# STM32F205xx register map
File version: 1.0
Registers are 32-bit, read-write, reset 0x0 unless marked. A register's access mark holds for its fields unless they carry their own. Offsets are from the block's base; [hi:lo] are bit positions; {n}, {i} and the like mark numbered series; 'fields as' and 'values as' point back to an identical list.

## TIM2 — TIM
Base 0x40000000
Same registers: TIM5 0x40000C00
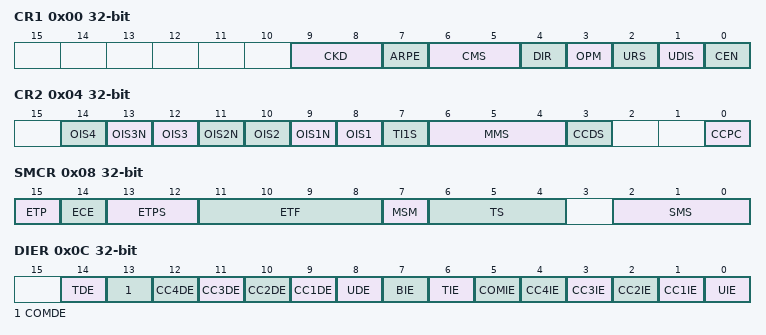
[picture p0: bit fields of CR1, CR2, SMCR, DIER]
0x00 CR1 — TIM control register 1
  [9:8] CKD — CKD[1:0] bits (clock division)
    0=DIV1 (tDTS=tCK_INT); 1=DIV2 (tDTS=2*tCK_INT); 2=DIV4 (tDTS=4*tCK_INT)
  [7] ARPE — Auto-reload preload enable
  [6:5] CMS — CMS[1:0] bits (Center-aligned mode selection)
  [4] DIR — Direction
    0=UP (Timer counter counts up); 1=DOWN (Timer counter counts down)
  [3] OPM — One pulse mode
    1=SINGLE (Counter stops counting at the next update event); 0=REPETITIVE (Counter is not stopped at update event)
  [2] URS — Update request source
    0=REGULAR (Counter overflow/underflow, Setting the UG bit or Update generation through the slave mode controller generates an update request); 1=COUNTER (Only counter overflow/underflow generates an update request)
  [1] UDIS — Update disable
  [0] CEN — Counter enable
0x04 CR2 — TIM control register 2
  [2n+6] OIS{n} (n=1..4) — Output Idle state {n} (OC{n} output)
  [13] OIS3N — Output Idle state 3 (OC3N output)
  [11] OIS2N — Output Idle state 2 (OC2N output)
  [9] OIS1N — Output Idle state 1 (OC1N output)
  [7] TI1S — TI1 Selection
  [6:4] MMS — MMS[2:0] bits (Master Mode Selection)
    0=RESET (UG bit from the TIMx_EGR register is used as trigger output); 1=ENABLE (Counter Enable signal (CNT_EN) is used as trigger output); 2=UPDATE (Update event is used as trigger output); 3=CC1IF (CC1 capture or a compare match is used as trigger output); {v}=OC{v-3}REF (OC{v-3}REF signal is used as trigger output) (v=4..7)
  [3] CCDS — Capture/Compare DMA Selection
    0=CC (CCx DMA request sent when CCx event occurs); 1=UPDATE (CCx DMA requests sent when update event occurs)
  [0] CCPC — Capture/Compare Preloaded Control
0x08 SMCR — TIM slave mode control register
  [15] ETP — External trigger polarity
  [14] ECE — External clock enable
  [13:12] ETPS — ETPS[1:0] bits (External trigger prescaler)
  [11:8] ETF — ETF[3:0] bits (External trigger filter)
  [7] MSM — Master/slave mode
  [6:4] TS — TS[2:0] bits (Trigger selection)
    {v}=ITR{v} (Internal Trigger {v} (ITR{v}) is used as trigger input) (v=0..3); 4=TI1F_ED (TI1 Edge Detector (TI1F_ED) is used as trigger input); 5=TI1FP1 (Filtered Timer Input 1 (TI1FP1) is used as trigger input); 6=TI2FP2 (Filtered Timer Input 2 (TI12P2) is used as trigger input); 7=ETRF (Filtered external Trigger (ETRF) is used as trigger input)
  [2:0] SMS — SMS[2:0] bits (Slave mode selection)
    1=X2_TI1 (Quadrature encoder mode 1, x2 mode - Counter counts up/down on TI1FP1 edge depending on TI2FP2 level); 2=X2_TI2 (Quadrature encoder mode 2, x2 mode - Counter counts up/down on TI2FP2 edge depending on TI1FP1 level); 3=X4_TI12 (Quadrature encoder mode 3, x4 mode - Counter counts up/down on both TI1FP1 and TI2FP2 edges depending on the level of the other input); 0=DISABLED (Slave mode disabled); 4=RESET (Reset Mode - Rising edge of the selected trigger input (TRGI) reinitializes the counter); 5=GATED (Gated Mode - The counter clock is enabled when the trigger input (TRGI) is high); 6=TRIGGER (Trigger Mode - The counter starts at a rising edge of the trigger TRGI)
0x0C DIER — TIM DMA/interrupt enable register
  [14] TDE — Trigger DMA request enable
  [13] COMDE — COM DMA request enable
  [n+8] CC{n}DE (n=1..4) — Capture/Compare {n} DMA request enable
  [8] UDE — Update DMA request enable
  [7] BIE — Break interrupt enable
  [6] TIE — Trigger interrupt enable
  [5] COMIE — COM interrupt enable
  [n] CC{n}IE (n=1..4) — Capture/Compare {n} interrupt enable
  [0] UIE — Update interrupt enable
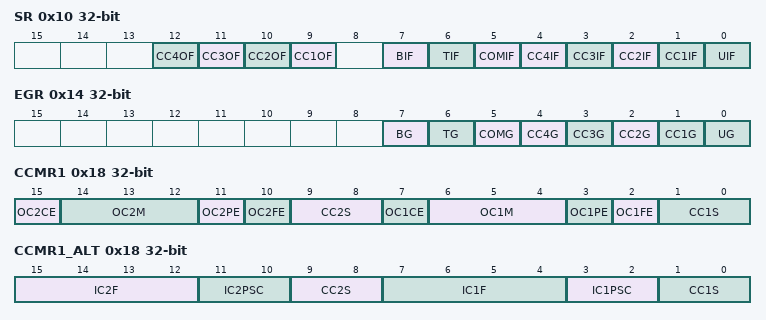
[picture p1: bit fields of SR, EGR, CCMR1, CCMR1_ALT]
0x10 SR — TIM status register
  [n+8] CC{n}OF (n=1..4) — Capture/Compare {n} Overcapture Flag
  [7] BIF — Break interrupt Flag
  [6] TIF — Trigger interrupt Flag
  [5] COMIF — COM interrupt Flag
  [n] CC{n}IF (n=1..4) — Capture/Compare {n} interrupt Flag
  [0] UIF — Update interrupt Flag
0x14 EGR — TIM event generation register
  [7] BG — Break Generation
  [6] TG — Trigger Generation
  [5] COMG — Capture/Compare Control Update Generation
  [n] CC{n}G (n=1..4) — Capture/Compare {n} Generation
  [0] UG — Update Generation
0x18 CCMR1 — TIM capture/compare mode register 1
  [15] OC2CE — Output Compare 2 Clear Enable
  [14:12] OC2M — OC2M[2:0] bits (Output Compare 2 Mode)
  [11] OC2PE — Output Compare 2 Preload enable
  [10] OC2FE — Output Compare 2 Fast enable
  [9:8] CC2S — CC2S[1:0] bits (Capture/Compare 2 Selection)
  [7] OC1CE — Output Compare 1Clear Enable
  [6:4] OC1M — OC1M[2:0] bits (Output Compare 1 Mode)
  [3] OC1PE — Output Compare 1 Preload enable
  [2] OC1FE — Output Compare 1 Fast enable
  [1:0] CC1S — CC1S[1:0] bits (Capture/Compare 1 Selection)
0x18 CCMR1_ALT (alternate view of CCMR1) — TIM capture/compare mode register 1
  [15:12] IC2F — IC2F[3:0] bits (Input Capture 2 Filter)
  [11:10] IC2PSC — IC2PSC[1:0] bits (Input Capture 2 Prescaler)
  [9:8] CC2S — CC2S[1:0] bits (Capture/Compare 2 Selection)
  [7:4] IC1F — IC1F[3:0] bits (Input Capture 1 Filter)
  [3:2] IC1PSC — IC1PSC[1:0] bits (Input Capture 1 Prescaler)
  [1:0] CC1S — CC1S[1:0] bits (Capture/Compare 1 Selection)
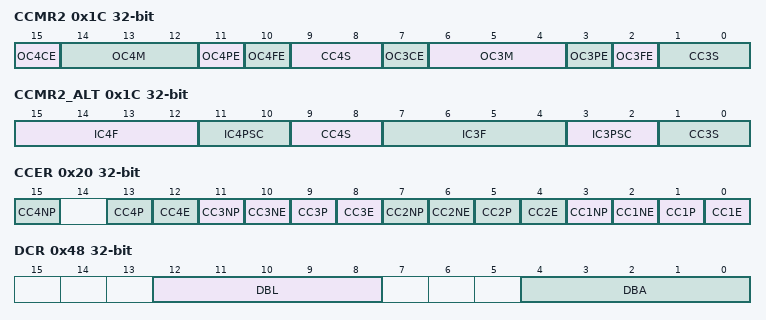
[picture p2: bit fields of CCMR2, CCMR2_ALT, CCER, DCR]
0x1C CCMR2 — TIM capture/compare mode register 2
  [15] OC4CE — Output Compare 4 Clear Enable
  [14:12] OC4M — OC4M[2:0] bits (Output Compare 4 Mode)
  [11] OC4PE — Output Compare 4 Preload enable
  [10] OC4FE — Output Compare 4 Fast enable
  [9:8] CC4S — CC4S[1:0] bits (Capture/Compare 4 Selection)
  [7] OC3CE — Output Compare 3 Clear Enable
  [6:4] OC3M — OC3M[2:0] bits (Output Compare 3 Mode)
  [3] OC3PE — Output Compare 3 Preload enable
  [2] OC3FE — Output Compare 3 Fast enable
  [1:0] CC3S — CC3S[1:0] bits (Capture/Compare 3 Selection)
0x1C CCMR2_ALT (alternate view of CCMR2) — TIM capture/compare mode register 2
  [15:12] IC4F — IC4F[3:0] bits (Input Capture 4 Filter)
  [11:10] IC4PSC — IC4PSC[1:0] bits (Input Capture 4 Prescaler)
  [9:8] CC4S — CC4S[1:0] bits (Capture/Compare 4 Selection)
  [7:4] IC3F — IC3F[3:0] bits (Input Capture 3 Filter)
  [3:2] IC3PSC — IC3PSC[1:0] bits (Input Capture 3 Prescaler)
  [1:0] CC3S — CC3S[1:0] bits (Capture/Compare 3 Selection)
0x20 CCER — TIM capture/compare enable register
  [4n-1] CC{n}NP (n=1..4) — Capture/Compare {n} Complementary output Polarity
  [4n-3] CC{n}P (n=1..4) — Capture/Compare {n} output Polarity
  [4n-4] CC{n}E (n=1..4) — Capture/Compare {n} output enable
  [10] CC3NE — Capture/Compare 3 Complementary output enable
  [6] CC2NE — Capture/Compare 2 Complementary output enable
  [2] CC1NE — Capture/Compare 1 Complementary output enable
0x24 CNT — TIM counter register
  [31:0] CNT — Counter Value
0x28 PSC — TIM prescaler
  [15:0] PSC — Prescaler Value
0x2C ARR — TIM auto-reload register
  [31:0] ARR — actual auto-reload Value
{0x30+4i} CCR{i} (i=1..4) — TIM capture/compare register {i}
  [15:0] CCR{i} — Capture/Compare {i} Value
0x48 DCR — TIM DMA control register
  [12:8] DBL — DBL[4:0] bits (DMA Burst Length)
  [4:0] DBA — DBA[4:0] bits (DMA Base Address)
0x4C DMAR — TIM DMA address for full transfer
  [15:0] DMAB — DMA register for burst accesses
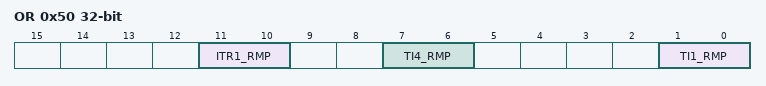
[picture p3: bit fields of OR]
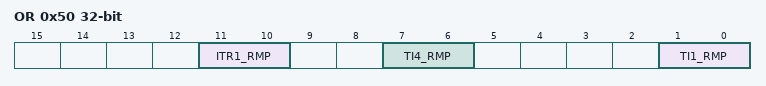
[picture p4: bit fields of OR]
0x50 OR — TIM option register
  [11:10] ITR1_RMP — ITR1_RMP[1:0] bits (TIM2 Internal trigger 1 remap)
  [7:6] TI4_RMP — TI4_RMP[1:0] bits (TIM5 Input 4 remap)
  [1:0] TI1_RMP — TI1_RMP[1:0] bits (TIM11 Input Capture 1 remap)

## TIM3 — TIM
Base 0x40000400
Same registers: TIM4 0x40000800
Registers as TIM2; these are added or differ:
0x24 CNT — TIM counter register
  [15:0] CNT — Counter Value
0x2C ARR — TIM auto-reload register
  [15:0] ARR — actual auto-reload Value
0x50 OR — TIM option register
  [11:10] ITR1_RMP — ITR1_RMP[1:0] bits (TIM2 Internal trigger 1 remap)
  [7:6] TI4_RMP — TI4_RMP[1:0] bits (TIM5 Input 4 remap)
  [1:0] TI1_RMP — TI1_RMP[1:0] bits (TIM11 Input Capture 1 remap)

## TIM1 — TIM
Base 0x40010000
Same registers: TIM8 0x40010400
Registers as TIM3; these are added or differ:
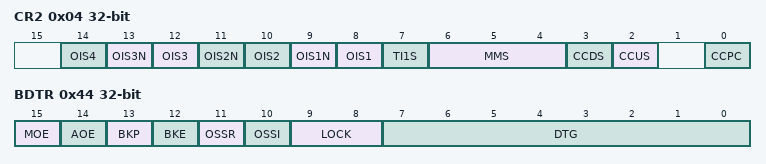
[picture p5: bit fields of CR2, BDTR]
0x04 CR2 — TIM control register 2
  [2n+6] OIS{n} (n=1..4) — Output Idle state {n} (OC{n} output)
  [13] OIS3N — Output Idle state 3 (OC3N output)
  [11] OIS2N — Output Idle state 2 (OC2N output)
  [9] OIS1N — Output Idle state 1 (OC1N output)
  [7] TI1S — TI1 Selection
  [6:4] MMS — MMS[2:0] bits (Master Mode Selection)
    values as TIM2.CR2.MMS
  [3] CCDS — Capture/Compare DMA Selection
    0=CC (CCx DMA request sent when CCx event occurs); 1=UPDATE (CCx DMA requests sent when update event occurs)
  [2] CCUS — Capture/Compare Control Update Selection
    0=ONLY (Capture/compare control bits are updated by setting the COMG bit only); 1=AND_TRGI (Capture/compare control bits are updated by setting the COMG bit or when a rising edge occurs on trigger input (TRGI))
  [0] CCPC — Capture/Compare Preloaded Control
0x30 RCR — TIM repetition counter register
  [7:0] REP — Repetition Counter Value
0x44 BDTR — TIM break and dead-time register
  [15] MOE — Main Output enable
  [14] AOE — Automatic Output enable
  [13] BKP — Break Polarity
    0=LOW (Break input BRK is active low); 1=HIGH (Break input BRK is active high)
  [12] BKE — Break enable
  [11] OSSR — Off-State Selection for Run mode
  [10] OSSI — Off-State Selection for Idle mode
  [9:8] LOCK — LOCK[1:0] bits (Lock Configuration)
    0=OFF (LOCK OFF - No bit is write protected); 1=LOCKLEVEL_1; 2=LOCKLEVEL_2; 3=LOCKLEVEL_3
  [7:0] DTG — DTG[0:7] bits (Dead-Time Generator set-up)
